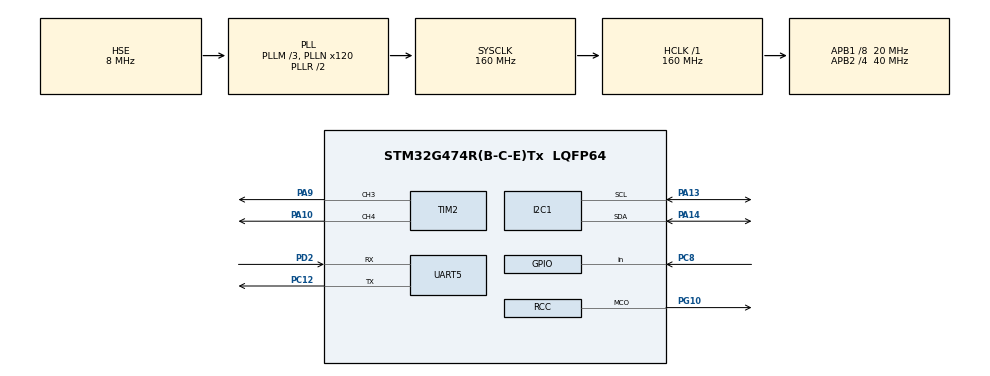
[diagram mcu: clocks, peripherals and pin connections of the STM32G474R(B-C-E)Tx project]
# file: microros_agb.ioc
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Dma.Request0=UART5_RX
Dma.Request1=UART5_TX
Dma.UART5_RX.0.Direction=DMA_PERIPH_TO_MEMORY
Dma.UART5_RX.0.EventEnable=DISABLE
Dma.UART5_RX.0.Instance=DMA1_Channel1
Dma.UART5_RX.0.MemDataAlignment=DMA_MDATAALIGN_BYTE
Dma.UART5_RX.0.MemInc=DMA_MINC_ENABLE
Dma.UART5_RX.0.Mode=DMA_CIRCULAR
Dma.UART5_RX.0.PeriphDataAlignment=DMA_PDATAALIGN_BYTE
Dma.UART5_RX.0.PeriphInc=DMA_PINC_DISABLE
Dma.UART5_RX.0.Polarity=HAL_DMAMUX_REQ_GEN_RISING
Dma.UART5_RX.0.Priority=DMA_PRIORITY_VERY_HIGH
Dma.UART5_RX.0.RequestNumber=1
Dma.UART5_RX.0.SignalID=NONE
Dma.UART5_RX.0.SyncEnable=DISABLE
Dma.UART5_RX.0.SyncPolarity=HAL_DMAMUX_SYNC_NO_EVENT
Dma.UART5_RX.0.SyncRequestNumber=1
Dma.UART5_RX.0.SyncSignalID=NONE
Dma.UART5_TX.1.Direction=DMA_MEMORY_TO_PERIPH
Dma.UART5_TX.1.EventEnable=DISABLE
Dma.UART5_TX.1.Instance=DMA1_Channel2
Dma.UART5_TX.1.MemDataAlignment=DMA_MDATAALIGN_BYTE
Dma.UART5_TX.1.MemInc=DMA_MINC_ENABLE
Dma.UART5_TX.1.Mode=DMA_NORMAL
Dma.UART5_TX.1.PeriphDataAlignment=DMA_PDATAALIGN_BYTE
Dma.UART5_TX.1.PeriphInc=DMA_PINC_DISABLE
Dma.UART5_TX.1.Polarity=HAL_DMAMUX_REQ_GEN_RISING
Dma.UART5_TX.1.Priority=DMA_PRIORITY_VERY_HIGH
Dma.UART5_TX.1.RequestNumber=1
Dma.UART5_TX.1.SignalID=NONE
Dma.UART5_TX.1.SyncEnable=DISABLE
Dma.UART5_TX.1.SyncPolarity=HAL_DMAMUX_SYNC_NO_EVENT
Dma.UART5_TX.1.SyncRequestNumber=1
Dma.UART5_TX.1.SyncSignalID=NONE
FREERTOS.Tasks01=defaultTask,24,2500,StartDefaultTask,Default,NULL,Static,defaultTaskBuffer,defaultTaskControlBlock
I2C1.Timing=0x00604E6E
Mcu.Family=STM32G4
Mcu.Name=STM32G474R(B-C-E)Tx
Mcu.Package=LQFP64
NVIC.DMA1_Channel1_IRQn=true\:5\:0\:false\:false\:true\:true\:false\:true\:true
NVIC.DMA1_Channel2_IRQn=true\:5\:0\:false\:false\:true\:true\:false\:true\:true
NVIC.PriorityGroup=NVIC_PRIORITYGROUP_4
NVIC.TIM1_UP_TIM16_IRQn=true\:15\:0\:false\:false\:true\:false\:false\:true\:true
NVIC.TimeBase=TIM1_UP_TIM16_IRQn
NVIC.TimeBaseIP=TIM1
NVIC.UART5_IRQn=true\:5\:0\:false\:false\:true\:true\:false\:true\:true
PA10.Signal=S_TIM2_CH4
PA13.Mode=I2C
PA13.Signal=I2C1_SCL
PA14.Mode=I2C
PA14.Signal=I2C1_SDA
PA9.Signal=S_TIM2_CH3
PC12.Mode=Asynchronous
PC12.Signal=UART5_TX
PC8.Signal=GPIO_Input
PD2.Mode=Asynchronous
PD2.Signal=UART5_RX
PF0-OSC_IN.Mode=HSE-External-Oscillator
PF0-OSC_IN.Signal=RCC_OSC_IN
PF1-OSC_OUT.Mode=HSE-External-Oscillator
PF1-OSC_OUT.Signal=RCC_OSC_OUT
PG10-NRST.Mode=Clock-out
PG10-NRST.Signal=RCC_MCO
ProjectManager.HeapSize=0x200
ProjectManager.StackSize=0x400
ProjectManager.TargetToolchain=Makefile
RCC.ADC12Freq_Value=160000000
RCC.ADC345Freq_Value=160000000
RCC.AHBFreq_Value=160000000
RCC.APB1CLKDivider=RCC_HCLK_DIV8
RCC.APB1Freq_Value=20000000
RCC.APB1TimFreq_Value=40000000
RCC.APB2CLKDivider=RCC_HCLK_DIV4
RCC.APB2Freq_Value=40000000
RCC.APB2TimFreq_Value=80000000
RCC.CortexFreq_Value=160000000
RCC.EXTERNAL_CLOCK_VALUE=12288000
RCC.HCLKFreq_Value=160000000
RCC.HSE_VALUE=8000000
RCC.HSI48_VALUE=48000000
RCC.HSI_VALUE=16000000
RCC.LSE_VALUE=32768
RCC.PLLM=RCC_PLLM_DIV3
RCC.PLLN=120
RCC.PLLSourceVirtual=RCC_PLLSOURCE_HSE
RCC.SYSCLKFreq_VALUE=160000000
RCC.SYSCLKSource=RCC_SYSCLKSOURCE_PLLCLK
RCC.USBFreq_Value=160000000
RCC.VCOOutputFreq_Value=320000000
SH.S_TIM2_CH3.0=TIM2_CH3,PWM Generation3 CH3
SH.S_TIM2_CH4.0=TIM2_CH4,PWM Generation4 CH4
TIM2.Channel-PWM\ Generation3\ CH3=TIM_CHANNEL_3
TIM2.Channel-PWM\ Generation4\ CH4=TIM_CHANNEL_4
VP_FREERTOS_VS_CMSIS_V2.Mode=CMSIS_V2
VP_SYS_VS_DBSignals.Mode=DisableDeadBatterySignals
VP_SYS_VS_tim1.Mode=TIM1
board=custom

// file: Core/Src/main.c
/* USER CODE BEGIN Header */
/**
  ******************************************************************************
  * @file           : main.c
  * @brief          : Main program body
  ******************************************************************************
  * @attention
  *
  * Copyright (c) 2025 STMicroelectronics.
  * All rights reserved.
  *
  * This software is licensed under terms that can be found in the LICENSE file
  * in the root directory of this software component.
  * If no LICENSE file comes with this software, it is provided AS-IS.
  *
  ******************************************************************************
  */
/* USER CODE END Header */
#include "main.h"
#include "cmsis_os.h"
#include "dma.h"
#include "i2c.h"
#include "tim.h"
#include "usart.h"
#include "gpio.h"

void SystemClock_Config(void);
void MX_FREERTOS_Init(void);

int main(void)
{

  /* MCU Configuration--------------------------------------------------------*/

  /* Reset of all peripherals, Initializes the Flash interface and the Systick. */
  HAL_Init();

  /* Configure the system clock */
  SystemClock_Config();

  /* Initialize all configured peripherals */
  MX_GPIO_Init();
  MX_DMA_Init();
  MX_UART5_Init();
  MX_TIM2_Init();
  MX_I2C1_Init();

  /* Init scheduler */
  osKernelInitialize();  /* Call init function for freertos objects (in cmsis_os2.c) */
  MX_FREERTOS_Init();

  /* Start scheduler */
  osKernelStart();

  /* We should never get here as control is now taken by the scheduler */

  /* Infinite loop */
  while (1)
  {

  }
}

void SystemClock_Config(void)
{
  RCC_OscInitTypeDef RCC_OscInitStruct = {0};
  RCC_ClkInitTypeDef RCC_ClkInitStruct = {0};

  /** Configure the main internal regulator output voltage
  */
  HAL_PWREx_ControlVoltageScaling(PWR_REGULATOR_VOLTAGE_SCALE1_BOOST);

  /** Initializes the RCC Oscillators according to the specified parameters
  * in the RCC_OscInitTypeDef structure.
  */
  RCC_OscInitStruct.OscillatorType = RCC_OSCILLATORTYPE_HSI|RCC_OSCILLATORTYPE_HSE;
  RCC_OscInitStruct.HSEState = RCC_HSE_ON;
  RCC_OscInitStruct.HSIState = RCC_HSI_ON;
  RCC_OscInitStruct.HSICalibrationValue = RCC_HSICALIBRATION_DEFAULT;
  RCC_OscInitStruct.PLL.PLLState = RCC_PLL_ON;
  RCC_OscInitStruct.PLL.PLLSource = RCC_PLLSOURCE_HSE;
  RCC_OscInitStruct.PLL.PLLM = RCC_PLLM_DIV3;
  RCC_OscInitStruct.PLL.PLLN = 120;
  RCC_OscInitStruct.PLL.PLLP = RCC_PLLP_DIV2;
  RCC_OscInitStruct.PLL.PLLQ = RCC_PLLQ_DIV2;
  RCC_OscInitStruct.PLL.PLLR = RCC_PLLR_DIV2;
  if (HAL_RCC_OscConfig(&RCC_OscInitStruct) != HAL_OK)
  {
    Error_Handler();
  }

  /** Initializes the CPU, AHB and APB buses clocks
  */
  RCC_ClkInitStruct.ClockType = RCC_CLOCKTYPE_HCLK|RCC_CLOCKTYPE_SYSCLK
                              |RCC_CLOCKTYPE_PCLK1|RCC_CLOCKTYPE_PCLK2;
  RCC_ClkInitStruct.SYSCLKSource = RCC_SYSCLKSOURCE_PLLCLK;
  RCC_ClkInitStruct.AHBCLKDivider = RCC_SYSCLK_DIV1;
  RCC_ClkInitStruct.APB1CLKDivider = RCC_HCLK_DIV8;
  RCC_ClkInitStruct.APB2CLKDivider = RCC_HCLK_DIV4;

  if (HAL_RCC_ClockConfig(&RCC_ClkInitStruct, FLASH_LATENCY_4) != HAL_OK)
  {
    Error_Handler();
  }
  HAL_RCC_MCOConfig(RCC_MCO_PG10, RCC_MCO1SOURCE_HSI, RCC_MCODIV_1);
}

void HAL_TIM_PeriodElapsedCallback(TIM_HandleTypeDef *htim)
{
  if (htim->Instance == TIM1)
  {
    HAL_IncTick();
  }
}

void Error_Handler(void)
{
  __disable_irq();
  while (1)
  {
  }
}

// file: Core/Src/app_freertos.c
/* USER CODE BEGIN Header */
/**
  ******************************************************************************
  * File Name          : app_freertos.c
  * Description        : Code for freertos applications
  ******************************************************************************
  * @attention
  *
  * Copyright (c) 2025 STMicroelectronics.
  * All rights reserved.
  *
  * This software is licensed under terms that can be found in the LICENSE file
  * in the root directory of this software component.
  * If no LICENSE file comes with this software, it is provided AS-IS.
  *
  ******************************************************************************
  */
/* USER CODE END Header */

#include "FreeRTOS.h"
#include "task.h"
#include "main.h"
#include "cmsis_os.h"
#include "tim.h"

typedef StaticTask_t osStaticThreadDef_t;

/* Definitions for defaultTask */
osThreadId_t defaultTaskHandle;
uint32_t defaultTaskBuffer[ 2500 ];
osStaticThreadDef_t defaultTaskControlBlock;
const osThreadAttr_t defaultTask_attributes = {
  .name = "defaultTask",
  .stack_mem = &defaultTaskBuffer[0],
  .stack_size = sizeof(defaultTaskBuffer),
  .cb_mem = &defaultTaskControlBlock,
  .cb_size = sizeof(defaultTaskControlBlock),
  .priority = (osPriority_t) osPriorityNormal,
};

osThreadId_t pwmTaskHandle;
uint32_t pwmTaskBuffer[512];          // stack (adjust if needed)
osStaticThreadDef_t pwmTaskControlBlock;
const osThreadAttr_t pwmTask_attributes = {
  .name = "pwmTask",
  .stack_mem = &pwmTaskBuffer[0],
  .stack_size = sizeof(pwmTaskBuffer),
  .cb_mem = &pwmTaskControlBlock,
  .cb_size = sizeof(pwmTaskControlBlock),
  .priority = (osPriority_t) osPriorityNormal,
};

void StartDefaultTask(void *argument);
void StartPWMTask(void *arg);

void MX_FREERTOS_Init(void); /* (MISRA C 2004 rule 8.1) */

void MX_FREERTOS_Init(void) {

  /* Create the thread(s) */
  /* creation of defaultTask */
  defaultTaskHandle = osThreadNew(StartDefaultTask, NULL, &defaultTask_attributes);
  pwmTaskHandle = osThreadNew(StartPWMTask, NULL, &pwmTask_attributes);

}

void StartDefaultTask(void *argument)
{
  /* USER CODE BEGIN StartDefaultTask */
  /* Infinite loop */
  for(;;)
  {
    osDelay (1);
  }
  /* USER CODE END StartDefaultTask */
}

void StartPWMTask(void *arg)
{

  for(;;)
  {
    osDelay(1);
  }

}
